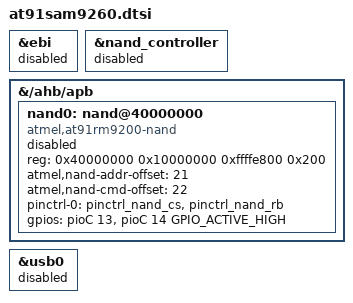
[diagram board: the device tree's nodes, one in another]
/* SPDX-License-Identifier: GPL-2.0-only */

&ebi {
	status = "disabled";
};

&nand_controller {
	status = "disabled";
};

&{/ahb/apb} {
	nand0: nand@40000000 {
		compatible = "atmel,at91rm9200-nand";
		#address-cells = <1>;
		#size-cells = <1>;
		reg = <0x40000000 0x10000000
		       0xffffe800 0x200
		      >;
		atmel,nand-addr-offset = <21>;
		atmel,nand-cmd-offset = <22>;
		pinctrl-names = "default";
		pinctrl-0 = <&pinctrl_nand_cs &pinctrl_nand_rb>;
		gpios = <&pioC 13 GPIO_ACTIVE_HIGH
			 &pioC 14 GPIO_ACTIVE_HIGH
			 0
			>;
		status = "disabled";
	};
};

&usb0 { /* currently hangs with DT-enabled driver */
	status = "disabled";
};
